# SN32F420 register map
Vendor: SONiX Technology Co., Ltd.; Series: SN32F420; File version: 1.00
CPU: CM0 r0p0, little endian, no MPU, no FPU, 2 interrupt priority bits
Registers are 32-bit, read-write, reset 0x0 unless marked. A register's access mark holds for its fields unless they carry their own. Offsets are from the block's base; [hi:lo] are bit positions.

## SN_PFPA — Peripheral Function Pin Assignment
Base 0x40042000
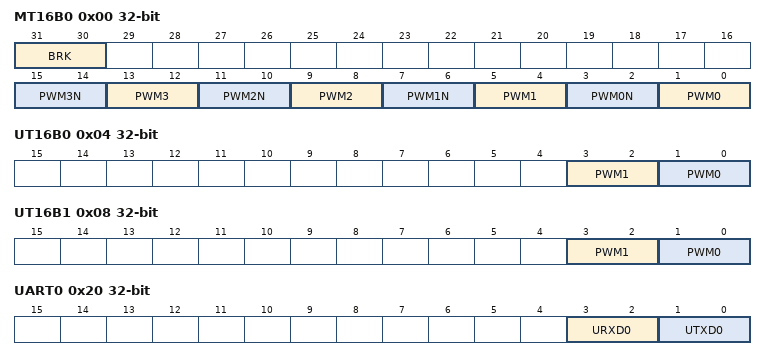
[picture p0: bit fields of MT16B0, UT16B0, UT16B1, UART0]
0x00 MT16B0 — Offset:0x00 PFPA for MT16B0 register
  [31:30] BRK — MT16B0_BRK assigned pin
    0=P1.4 (MT16B0_BRK=P1.4); 1=P3.5 (MT16B0_BRK=P3.5); 2=P3.7 (MT16B0_BRK=P3.7); 3=P1.0 (MT16B0_BRK=P1.0)
  [15:14] PWM3N — MT16B0_PWM3N assigned pin
    0=P3.5 (MT16B0_PWM3N=P3.5); 1=P3.8 (MT16B0_PWM3N=P3.8); 2=P0.2 (MT16B0_PWM3N=P0.2); 3=P2.4 (MT16B0_PWM3N=P2.4)
  [13:12] PWM3 — MT16B0_PWM3 assigned pin
    0=P3.4 (MT16B0_PWM3=P3.4); 1=P3.7 (MT16B0_PWM3=P3.7); 2=P1.7 (MT16B0_PWM3=P1.7); 3=P2.3 (MT16B0_PWM3=P2.3)
  [11:10] PWM2N — MT16B0_PWM2N assigned pin
    0=P0.7 (MT16B0_PWM2N=P0.7); 1=P3.4 (MT16B0_PWM2N=P3.4); 2=P1.6 (MT16B0_PWM2N=P1.6); 3=P1.7 (MT16B0_PWM2N=P1.7)
  [9:8] PWM2 — MT16B0_PWM2 assigned pin
    0=P0.6 (MT16B0_PWM2=P0.6); 1=P0.4 (MT16B0_PWM2=P0.4); 2=P1.4 (MT16B0_PWM2=P1.4); 3=P1.2 (MT16B0_PWM2=P1.2)
  [7:6] PWM1N — MT16B0_PWM1N assigned pin
    0=P0.5 (MT16B0_PWM1N=P0.5); 1=P0.6 (MT16B0_PWM1N=P0.6); 2=P1.3 (MT16B0_PWM1N=P1.3); 3=P1.4 (MT16B0_PWM1N=P1.4)
  [5:4] PWM1 — MT16B0_PWM1 assigned pin
    0=P0.4 (MT16B0_PWM1=P0.4); 1=P0.3 (MT16B0_PWM1=P0.3); 2=P1.2 (MT16B0_PWM1=P1.2); 3=P1.1 (MT16B0_PWM1=P1.1)
  [3:2] PWM0N — MT16B0_PWM0N assigned pin
    0=P0.3 (MT16B0_PWM0N=P0.3); 1=P0.5 (MT16B0_PWM0N=P0.5); 2=P1.1 (MT16B0_PWM0N=P1.1); 3=P1.3 (MT16B0_PWM0N=P1.3)
  [1:0] PWM0 — MT16B0_PWM0 assigned pin
    0=P0.2 (MT16B0_PWM0=P0.2); 1=P1.7 (MT16B0_PWM0=P1.7); 2=P1.0 (MT16B0_PWM0=P1.0); 3=P2.4 (MT16B0_PWM0=P2.4)
0x04 UT16B0 — Offset:0x04 PFPA for UT16B0 register
  [3:2] PWM1 — UT16B0_PWM1 assigned pin
    0=P2.1 (UT16B0_PWM1=P2.1); 1=P1.3 (UT16B0_PWM1=P1.3); 2=P1.1 (UT16B0_PWM1=P1.1); 3=P0.7 (UT16B0_PWM1=P0.7)
  [1:0] PWM0 — UT16B0_PWM0 assigned pin
    0=P2.0 (UT16B0_PWM0=P2.0); 1=P1.2 (UT16B0_PWM0=P1.2); 2=P1.0 (UT16B0_PWM0=P1.0); 3=P0.6 (UT16B0_PWM0=P0.6)
0x08 UT16B1 — Offset:0x08 PFPA for UT16B1 register
  [3:2] PWM1 — UT16B1_PWM1 assigned pin
    0=P0.5 (UT16B1_PWM1=P0.5); 1=P3.9 (UT16B1_PWM1=P3.9); 2=P2.3 (UT16B1_PWM1=P2.3); 3=P3.7 (UT16B1_PWM1=P3.7)
  [1:0] PWM0 — UT16B1_PWM0 assigned pin
    0=P0.4 (UT16B1_PWM0=P0.4); 1=P3.8 (UT16B1_PWM0=P3.8); 2=P2.2 (UT16B1_PWM0=P2.2); 3=P3.6 (UT16B1_PWM0=P3.6)
0x20 UART0 — Offset:0x20 PFPA for UART0 register
  [3:2] URXD0 — UART0_URXD0 assigned pin
    0=P1.0 (URXD0=P1.0); 1=P2.0 (URXD0=P2.0); 2=P1.6 (URXD0=P1.6); 3=P0.6 (URXD0=P0.6)
  [1:0] UTXD0 — UART0_UTXD0 assigned pin
    0=P1.1 (UTXD0=P1.1); 1=P2.1 (UTXD0=P2.1); 2=P1.7 (UTXD0=P1.7); 3=P0.7 (UTXD0=P0.7)
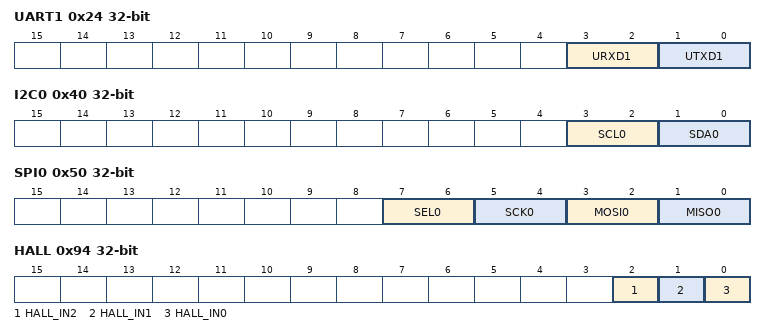
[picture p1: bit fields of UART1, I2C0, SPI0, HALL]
0x24 UART1 — Offset:0x24 PFPA for UART1 register
  [3:2] URXD1 — UART1_URXD1 assigned pin
    0=P1.2 (URXD1=P1.2); 1=P3.8 (URXD1=P3.8); 2=P3.4 (URXD1=P3.4); 3=P0.4 (URXD1=P0.4)
  [1:0] UTXD1 — UART1_UTXD1 assigned pin
    0=P1.3 (UTXD1=P1.3); 1=P3.9 (UTXD1=P3.9); 2=P3.5 (UTXD1=P3.5); 3=P0.5 (UTXD1=P0.5)
0x40 I2C0 — Offset:0x40 PFPA for I2C0 register
  [3:2] SCL0 — I2C_SCL0 assigned pin
    0=P1.0 (SCL0=P1.0); 1=P1.2 (SCL0=P1.2); 2=P3.4 (SCL0=P3.4); 3=P3.8 (SCL0=P3.8)
  [1:0] SDA0 — I2C_SDA0 assigned pin
    0=P1.1 (SDA0=P1.1); 1=P1.3 (SDA0=P1.3); 2=P3.5 (SDA0=P3.5); 3=P3.9 (SDA0=P3.9)
0x50 SPI0 — Offset:0x50 PFPA for SPI0 register
  [7:6] SEL0 — SPI_SEL0 assigned pin
    0=P1.1 (SEL0=P1.1); 1=P3.7 (SEL0=P3.7); 2=P0.3 (SEL0=P0.3); 3=P2.2 (SEL0=P2.2)
  [5:4] SCK0 — SPI_SCK0 assigned pin
    0=P1.0 (SCK0=P1.0); 1=P3.8 (SCK0=P3.8); 2=P0.2 (SCK0=P0.2); 3=P2.1 (SCK0=P2.1)
  [3:2] MOSI0 — SPI_MOSI0 assigned pin
    0=P1.3 (MOSI0=P1.3); 1=P3.4 (MOSI0=P3.4); 2=P0.5 (MOSI0=P0.5); 3=P2.4 (MOSI0=P2.4)
  [1:0] MISO0 — SPI_MISO0 assigned pin
    0=P1.2 (MISO0=P1.2); 1=P3.5 (MISO0=P3.5); 2=P0.4 (MISO0=P0.4); 3=P2.3 (MISO0=P2.3)
0x94 HALL — Offset:0x94 PFPA for HALL register
  [2] HALL_IN2 — HALL_IN2 assigned pin
    0=P3.9 (HALL_IN3=P3.9); 1=P1.4 (HALL_IN3=P1.4)
  [1] HALL_IN1 — HALL_IN1 assigned pin
    0=P3.8 (HALL_IN1=P3.8); 1=P1.3 (HALL_IN1=P1.3)
  [0] HALL_IN0 — HALL_IN0 assigned pin
    0=P3.7 (HALL_IN0=P3.7); 1=P1.2 (HALL_IN0=P1.2)
